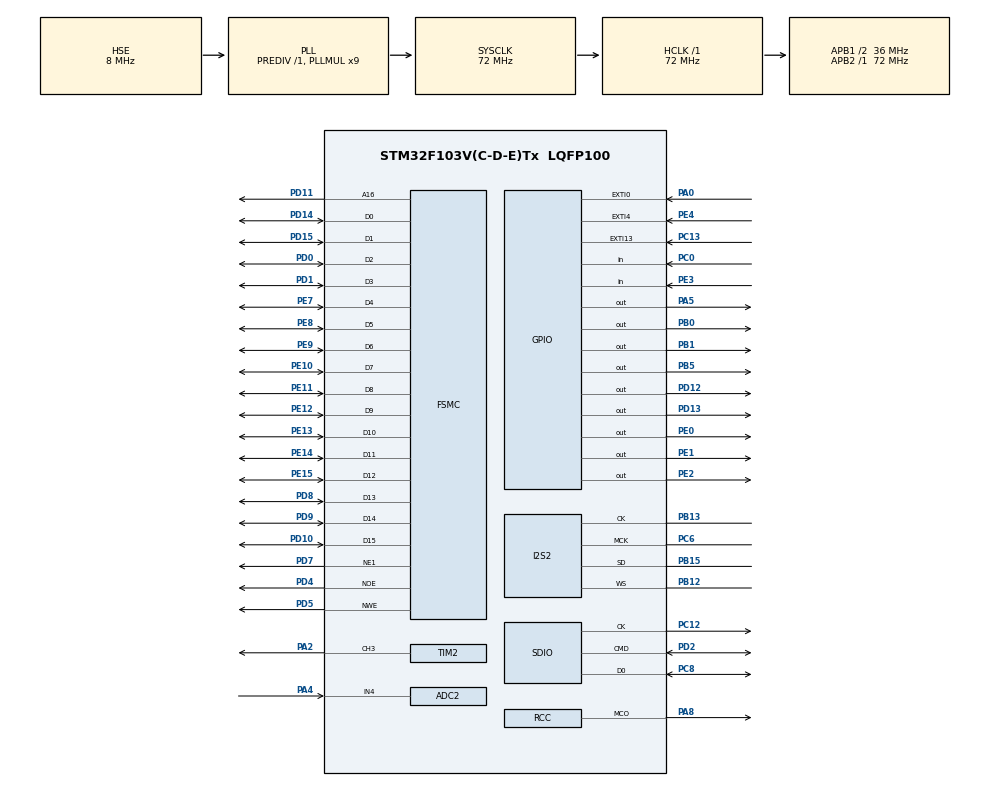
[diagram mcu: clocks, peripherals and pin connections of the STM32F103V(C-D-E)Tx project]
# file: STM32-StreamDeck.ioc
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ADC2.Channel-0\#ChannelRegularConversion=ADC_CHANNEL_4
ADC2.NbrOfConversionFlag=1
ADC2.Rank-0\#ChannelRegularConversion=1
ADC2.SamplingTime-0\#ChannelRegularConversion=ADC_SAMPLETIME_55CYCLES_5
Dma.Request0=SPI2_TX
Dma.SPI2_TX.0.Direction=DMA_MEMORY_TO_PERIPH
Dma.SPI2_TX.0.Instance=DMA1_Channel5
Dma.SPI2_TX.0.MemDataAlignment=DMA_MDATAALIGN_HALFWORD
Dma.SPI2_TX.0.MemInc=DMA_MINC_ENABLE
Dma.SPI2_TX.0.Mode=DMA_CIRCULAR
Dma.SPI2_TX.0.PeriphDataAlignment=DMA_PDATAALIGN_HALFWORD
Dma.SPI2_TX.0.PeriphInc=DMA_PINC_DISABLE
Dma.SPI2_TX.0.Priority=DMA_PRIORITY_LOW
I2S2.AudioFreq=I2S_AUDIOFREQ_16K
I2S2.CPOL=I2S_CPOL_LOW
I2S2.DataFormat=I2S_DATAFORMAT_16B_EXTENDED
I2S2.ErrorAudioFreq=-2.34 %
I2S2.Instance=SPI$Index
I2S2.MCLKOutput=I2S_MCLKOUTPUT_ENABLE
I2S2.RealAudioFreq=15.625 KHz
I2S2.VirtualMode=I2S_MODE_MASTER
Mcu.Family=STM32F1
Mcu.Name=STM32F103V(C-D-E)Tx
Mcu.Package=LQFP100
NVIC.DMA1_Channel5_IRQn=true\:0\:0\:false\:false\:true\:false\:true\:true
NVIC.EXTI0_IRQn=true\:0\:0\:false\:false\:true\:true\:true\:true
NVIC.EXTI15_10_IRQn=true\:0\:0\:false\:false\:true\:true\:true\:true
NVIC.EXTI4_IRQn=true\:0\:0\:false\:false\:true\:true\:true\:true
NVIC.PriorityGroup=NVIC_PRIORITYGROUP_4
NVIC.TIM1_UP_IRQn=true\:0\:0\:false\:false\:true\:true\:true\:true
OSC_IN.Mode=HSE-External-Oscillator
OSC_IN.Signal=RCC_OSC_IN
OSC_OUT.Mode=HSE-External-Oscillator
OSC_OUT.Signal=RCC_OSC_OUT
PA0-WKUP.GPIO_PuPd=GPIO_PULLDOWN
PA0-WKUP.Signal=GPXTI0
PA13.Mode=Serial_Wire
PA13.Signal=SYS_JTMS-SWDIO
PA14.Mode=Serial_Wire
PA14.Signal=SYS_JTCK-SWCLK
PA2.Signal=S_TIM2_CH3
PA4.Signal=ADCx_IN4
PA5.GPIO_Speed=GPIO_SPEED_FREQ_HIGH
PA5.PinState=GPIO_PIN_RESET
PA5.Signal=GPIO_Output
PA8.Mode=Clock-out
PA8.Signal=RCC_MCO
PB0.GPIO_Speed=GPIO_SPEED_FREQ_HIGH
PB0.PinState=GPIO_PIN_SET
PB0.Signal=GPIO_Output
PB1.GPIO_Speed=GPIO_SPEED_FREQ_HIGH
PB1.PinState=GPIO_PIN_SET
PB1.Signal=GPIO_Output
PB12.GPIO_Mode=GPIO_MODE_AF_PP
PB12.GPIO_Speed=GPIO_SPEED_FREQ_HIGH
PB12.Mode=Half_Duplex_Master_TX
PB12.Signal=I2S2_WS
PB13.GPIO_Mode=GPIO_MODE_AF_PP
PB13.GPIO_Speed=GPIO_SPEED_FREQ_HIGH
PB13.Mode=Half_Duplex_Master_TX
PB13.Signal=I2S2_CK
PB15.GPIO_Mode=GPIO_MODE_AF_PP
PB15.GPIO_Speed=GPIO_SPEED_FREQ_HIGH
PB15.Mode=Half_Duplex_Master_TX
PB15.Signal=I2S2_SD
PB5.GPIO_Speed=GPIO_SPEED_FREQ_HIGH
PB5.PinState=GPIO_PIN_SET
PB5.Signal=GPIO_Output
PC0.GPIO_PuPd=GPIO_PULLDOWN
PC0.Signal=GPIO_Input
PC12.Mode=SD_1_bit
PC12.Signal=SDIO_CK
PC13-TAMPER-RTC.GPIO_PuPd=GPIO_PULLDOWN
PC13-TAMPER-RTC.Signal=GPXTI13
PC14-OSC32_IN.Mode=LSE-External-Oscillator
PC14-OSC32_IN.Signal=RCC_OSC32_IN
PC15-OSC32_OUT.Mode=LSE-External-Oscillator
PC15-OSC32_OUT.Signal=RCC_OSC32_OUT
PC6.GPIO_Mode=GPIO_MODE_AF_PP
PC6.GPIO_Speed=GPIO_SPEED_FREQ_HIGH
PC6.Mode=Master_Clock_Activated
PC6.Signal=I2S2_MCK
PC8.Mode=SD_1_bit
PC8.Signal=SDIO_D0
PD0.Mode=16b-d1
PD0.Signal=FSMC_D2
PD1.Mode=16b-d1
PD1.Signal=FSMC_D3
PD10.Mode=16b-d1
PD10.Signal=FSMC_D15
PD11.Mode=A16_1
PD11.Signal=FSMC_A16
PD12.GPIO_Speed=GPIO_SPEED_FREQ_HIGH
PD12.PinState=GPIO_PIN_RESET
PD12.Signal=GPIO_Output
PD13.GPIO_Speed=GPIO_SPEED_FREQ_HIGH
PD13.Signal=GPIO_Output
PD14.Mode=16b-d1
PD14.Signal=FSMC_D0
PD15.Mode=16b-d1
PD15.Signal=FSMC_D1
PD2.Mode=SD_1_bit
PD2.Signal=SDIO_CMD
PD4.Mode=Lcd1
PD4.Signal=FSMC_NOE
PD5.Mode=Lcd1
PD5.Signal=FSMC_NWE
PD7.Mode=NorPsramChipSelect1_1
PD7.Signal=FSMC_NE1
PD8.Mode=16b-d1
PD8.Signal=FSMC_D13
PD9.Mode=16b-d1
PD9.Signal=FSMC_D14
PE0.GPIO_Speed=GPIO_SPEED_FREQ_HIGH
PE0.Signal=GPIO_Output
PE1.GPIO_Speed=GPIO_SPEED_FREQ_HIGH
PE1.Signal=GPIO_Output
PE10.Mode=16b-d1
PE10.Signal=FSMC_D7
PE11.Mode=16b-d1
PE11.Signal=FSMC_D8
PE12.Mode=16b-d1
PE12.Signal=FSMC_D9
PE13.Mode=16b-d1
PE13.Signal=FSMC_D10
PE14.Mode=16b-d1
PE14.Signal=FSMC_D11
PE15.Mode=16b-d1
PE15.Signal=FSMC_D12
PE2.GPIO_Speed=GPIO_SPEED_FREQ_HIGH
PE2.Signal=GPIO_Output
PE3.GPIO_PuPd=GPIO_PULLUP
PE3.Signal=GPIO_Input
PE4.GPIO_ModeDefaultEXTI=GPIO_MODE_IT_FALLING
PE4.GPIO_PuPd=GPIO_PULLUP
PE4.Signal=GPXTI4
PE7.Mode=16b-d1
PE7.Signal=FSMC_D4
PE8.Mode=16b-d1
PE8.Signal=FSMC_D5
PE9.Mode=16b-d1
PE9.Signal=FSMC_D6
ProjectManager.HeapSize=0x200
ProjectManager.StackSize=0x400
ProjectManager.TargetToolchain=STM32CubeIDE
RCC.ADCPresc=RCC_ADCPCLK2_DIV6
RCC.AHBFreq_Value=72000000
RCC.APB1CLKDivider=RCC_HCLK_DIV2
RCC.APB1Freq_Value=36000000
RCC.APB1TimFreq_Value=72000000
RCC.APB2Freq_Value=72000000
RCC.APB2TimFreq_Value=72000000
RCC.HCLKFreq_Value=72000000
RCC.PLLMUL=RCC_PLL_MUL9
RCC.PLLSourceVirtual=RCC_PLLSOURCE_HSE
RCC.RCC_MCOSource=RCC_MCO1SOURCE_PLLCLK
RCC.SYSCLKFreq_VALUE=72000000
RCC.SYSCLKSource=RCC_SYSCLKSOURCE_PLLCLK
RCC.USBFreq_Value=72000000
SDIO.ClockDiv=4
SH.ADCx_IN4.0=ADC2_IN4,IN4
SH.S_TIM2_CH3.0=TIM2_CH3,PWM Generation3 CH3
TIM1.Period=100-1
TIM1.Prescaler=72-1
TIM1.TIM_MasterOutputTrigger=TIM_TRGO_UPDATE
TIM2.Channel-PWM\ Generation3\ CH3=TIM_CHANNEL_3
TIM2.Period=1000-1
TIM2.Prescaler=72-1
TIM2.Pulse-PWM\ Generation3\ CH3=500
TIM2.TIM_MasterOutputTrigger=TIM_TRGO_UPDATE
VP_FATFS_VS_SDIO.Mode=SDIO
VP_TIM1_VS_ClockSourceINT.Mode=Internal
VP_TIM2_VS_ClockSourceINT.Mode=Internal
board=custom

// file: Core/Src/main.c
/* USER CODE BEGIN Header */
/**
  ******************************************************************************
  * @file           : main.c
  * @brief          : Main program body
  ******************************************************************************
  * @attention
  *
  * Copyright (c) 2023 STMicroelectronics.
  * All rights reserved.
  *
  * This software is licensed under terms that can be found in the LICENSE file
  * in the root directory of this software component.
  * If no LICENSE file comes with this software, it is provided AS-IS.
  *
  ******************************************************************************
  */
/* USER CODE END Header */
#include "main.h"
#include "fatfs.h"

/* USER CODE BEGIN Includes */
#include "files.h"
#include "math.h"
#include "pcm.h"
#include <stdio.h>
#include <string.h>
#include "lcdtp.h"
#include "xpt2046.h"
#include "pcm.h"
/* USER CODE END Includes */

/* USER CODE BEGIN PD */
#define usScreenWidth 240
#define usScreenHeight 320
/* USER CODE END PD */

 ADC_HandleTypeDef hadc2;

I2S_HandleTypeDef hi2s2;
DMA_HandleTypeDef hdma_spi2_tx;

SD_HandleTypeDef hsd;

TIM_HandleTypeDef htim1;
TIM_HandleTypeDef htim2;

SRAM_HandleTypeDef hsram1;

/* USER CODE BEGIN PV */

/* Flags */
uint16_t actionFlag = 0, drawGUIFlag = 1, drawButtonsFlag = 1;
uint8_t SDCardStatus = 0;

typedef enum {
  mainMenuTask,
  configMenuTask,
  audiofxConfigTask,
  displayConfigTask,
  dvConfigTask,
  hiddenConfigTask,
  threeFPSRGBTask,
} GUITask;

GUITask curGUITask = mainMenuTask;

 float value = 0.2;
 uint32_t var;
 uint32_t sine_val[100];

 #define PI 3.1415926

 void getSineVal() {
 	for (int i = 0; i < 100; i++) {
 		sine_val[i] = (((sin(i*2*PI/100)+1)*(255/2))*0.5);

 	}
 }
 uint8_t updateLCDStartPlay = 1;
 uint8_t playPCMFlag = 0;
 void HAL_GPIO_EXTI_Callback(uint16_t GPIO_Pin) {
  if (GPIO_Pin == GPIO_PIN_0) {
    if (curGUITask != threeFPSRGBTask) {
      nextSongFlag = 1;
    }
    kay = 1;
  }
	if (GPIO_Pin == GPIO_PIN_13) {
		playPCMFlag = playPCMFlag == 0 ? 1 : 0;
		if (!playPCMFlag) {
			drawGUIFlag = 1;
      drawButtonsFlag = 1;
		}
		updateLCDStartPlay = 1;
 	}
}

// void HAL_TIM_PeriodElapsedCallback(TIM_HandleTypeDef *htim) {
//     if (htim->Instance == TIM1) {
//         if (pcmDataToRead > 0) {
//             HAL_DAC_SetValue(&hdac, DAC_CHANNEL_1, DAC_ALIGN_8B_R, pcmBuffer[pcmBufferIndex]);
//             HAL_DAC_SetValue(&hdac, DAC_CHANNEL_2, DAC_ALIGN_8B_R, pcmBuffer[pcmBufferIndex+1]);
//             pcmBufferIndex += 2;
//             pcmDataToRead--;
//         }
//     }
// }

const uint16_t triangle_wave[]  = {
0x400,0x800,0xc00,0x1000,0x1400,0x1800,0x1c00,0x2000,
0x2400,0x2800,0x2c00,0x3000,0x3400,0x3800,0x3c00,0x4000,
0x4400,0x4800,0x4c00,0x5000,0x5400,0x5800,0x5c00,0x6000,
0x6400,0x6800,0x6c00,0x7000,0x7400,0x7800,0x7c00,0x8000,
0x83ff,0x87ff,0x8bff,0x8fff,0x93ff,0x97ff,0x9bff,0x9fff,
0xa3ff,0xa7ff,0xabff,0xafff,0xb3ff,0xb7ff,0xbbff,0xbfff,
0xc3ff,0xc7ff,0xcbff,0xcfff,0xd3ff,0xd7ff,0xdbff,0xdfff,
0xe3ff,0xe7ff,0xebff,0xefff,0xf3ff,0xf7ff,0xfbff,0xffff,
0xfbff,0xf7ff,0xf3ff,0xefff,0xebff,0xe7ff,0xe3ff,0xdfff,
0xdbff,0xd7ff,0xd3ff,0xcfff,0xcbff,0xc7ff,0xc3ff,0xbfff,
0xbbff,0xb7ff,0xb3ff,0xafff,0xabff,0xa7ff,0xa3ff,0x9fff,
0x9bff,0x97ff,0x93ff,0x8fff,0x8bff,0x87ff,0x83ff,0x8000,
0x7c00,0x7800,0x7400,0x7000,0x6c00,0x6800,0x6400,0x6000,
0x5c00,0x5800,0x5400,0x5000,0x4c00,0x4800,0x4400,0x4000,
0x3c00,0x3800,0x3400,0x3000,0x2c00,0x2800,0x2400,0x2000,
0x1c00,0x1800,0x1400,0x1000,0xc00,0x800,0x400,0x0,
};
const uint16_t sin_tbl_int[91] = {	    0,   572,  1144,  1715,  2286,  2856,  3425,  3993,  4560,  5126,
									 5690,  6252,  6813,  7371,  7927,  8481,  9032,  9580, 10126, 10668,
									11207, 11743, 12275, 12803, 13328, 13848, 14365, 14876, 15384, 15886,
									16384, 16877, 17364, 17847, 18324, 18795, 19261, 19720, 20174, 20622,
									21063, 21498, 21926, 22348, 22763, 23170, 23571, 23965, 24351, 24730,
									25102, 25466, 25822, 26170, 26510, 26842, 27166, 27482, 27789, 28088,
									28378, 28660, 28932, 29197, 29452, 29698, 29935, 30163, 30382, 30592,
									30792, 30983, 31164, 31336, 31499, 31651, 31795, 31928, 32052, 32166,
									32270, 32365, 32449, 32524, 32588, 32643, 32688, 32723, 32748, 32763,
									32768 };
/* Strings */
char * pStr = 0, cStr [10];

uint16_t inputSrc = 0 /* 0 = SD | 1 = 3.5mm */;		// See xpt2046.c \ audiofxConfig()
int kay = 0 /* K1 flag */, kerry = 0 /* K2 flag */;
uint16_t trueTone = 0 /* LDR trigger */, colourP = 0;	// Display colour preset
uint16_t shock = 0 /* Dynamic vibration trigger */, buzz = 1;	// 1 = Mildest | 3 = Strongest
uint16_t ruler;		// ADC2
uint16_t chovy[3];	// ADC2 Read buffer
/* USER CODE END PV */

void SystemClock_Config(void);
static void MX_GPIO_Init(void);
static void MX_FSMC_Init(void);
static void MX_SDIO_SD_Init(void);
static void MX_TIM1_Init(void);
static void MX_TIM2_Init(void);
static void MX_DMA_Init(void);
static void MX_I2S2_Init(void);
static void MX_ADC2_Init(void);
/* USER CODE BEGIN PFP */
uint8_t virtualAudioPlayerTask() {
	if (playPCMFlag) {
		// LCD_Clear (0, 0, 240, 320, BACKGROUND);
		scanFiles("0:/");
		return 1;
	} else {
		return 0;
	}
}
/* USER CODE END PFP */

/* USER CODE BEGIN 0 */
uint16_t testingIntensity = 0;
void dvModule (void) {
	// intensity = getAudioIntensity();
//  testingIntensity++;
//  if (testingIntensity > 100) {
//    testingIntensity = 0;
//  }
//	currentAudioIntensity = testingIntensity;			// For testing purposes

	/**
	 * I originally planned to change the voltage
	 * After testing I found out adjusting the vibration time achieves the same effect,
	 * and is way more doable than the above operation,
	 * so here we are ;)
	 */
	if (shock == 1) {
		// switch (buzz) {
		// 	case 1:
		// 		HAL_GPIO_WritePin(GPIOA, GPIO_PIN_5, GPIO_PIN_RESET);
		// 		HAL_Delay(100 - (currentAudioIntensity / 3));
		// 		HAL_GPIO_WritePin(GPIOA, GPIO_PIN_5,   GPIO_PIN_SET);
		// 		break;
		// 	case 2:
		// 		HAL_GPIO_WritePin(GPIOA, GPIO_PIN_5,   GPIO_PIN_RESET);
		// 		HAL_Delay(100 - (currentAudioIntensity * 2 / 3));
		// 		HAL_GPIO_WritePin(GPIOA, GPIO_PIN_5, GPIO_PIN_SET);
		// 		break;
		// 	case 3:
		// 		HAL_GPIO_WritePin(GPIOA, GPIO_PIN_5,   GPIO_PIN_RESET);
		// 		HAL_Delay(100 - currentAudioIntensity);
		// 		HAL_GPIO_WritePin(GPIOA, GPIO_PIN_5, GPIO_PIN_SET);
		// 		break;
		// }
    currentAudioIntensity = currentAudioIntensity / 6 * (buzz+3);
    if (buzz == 3 ) {
      currentAudioIntensity = currentAudioIntensity * 1.5;
      currentAudioIntensity > 1000 ? currentAudioIntensity = 1000 : currentAudioIntensity;

    }
    __HAL_TIM_SET_COMPARE(&htim2, TIM_CHANNEL_3, currentAudioIntensity);
	}
	return;
}

/* USER CODE END 0 */

int main(void)
{

  /* MCU Configuration--------------------------------------------------------*/

  /* Reset of all peripherals, Initializes the Flash interface and the Systick. */
  HAL_Init();

  /* Configure the system clock */
  SystemClock_Config();

  /* Initialize all configured peripherals */
  MX_GPIO_Init();
  MX_FSMC_Init();
  MX_SDIO_SD_Init();
  MX_FATFS_Init();
  MX_TIM1_Init();
  MX_TIM2_Init();
  MX_DMA_Init();
  MX_I2S2_Init();
  MX_ADC2_Init();
  /* USER CODE BEGIN 2 */

	FATFS myFATFS;
	FIL myFILE;
	UINT numberofbytes;
	char myPath[] = "TEST.TXT\0";
	char myData[] = "Hello World\0";
	FRESULT res;

	res = f_mount(&myFATFS,SDPath,1);
	if (res == FR_OK)
	{
    SDCardStatus = 1;
		HAL_GPIO_WritePin(GPIOB, GPIO_PIN_0,GPIO_PIN_RESET);
		f_open(&myFILE, myPath, FA_WRITE |FA_CREATE_ALWAYS);
		f_write(&myFILE, myData, sizeof(myData), &numberofbytes);
		f_close(&myFILE);
		HAL_Delay(1000);
		HAL_GPIO_WritePin(GPIOB, GPIO_PIN_1,GPIO_PIN_RESET);
	}
	else
	{
    SDCardStatus = 0;
		HAL_GPIO_WritePin(GPIOB, GPIO_PIN_5,GPIO_PIN_RESET);
	}

  macXPT2046_CS_DISABLE();
  LCD_INIT();
  /* Boot splash */
  pStr = "Welcome to Stream Deck!";
  LCD_DrawString_Color ( ( usScreenWidth - ( strlen ( pStr ) - 7 ) * WIDTH_EN_CHAR ) >> 2, usScreenHeight >> 1, pStr, BACKGROUND, BLACK );
  HAL_Delay(1000);
  LCD_Clear(0, 0, 240, 320, BACKGROUND);
//  HAL_GPIO_WritePin(GPIOA, GPIO_PIN_5,   GPIO_PIN_RESET);		// Debugging
  HAL_ADCEx_Calibration_Start(&hadc2);
  HAL_ADC_Start(&hadc2);
  HAL_ADC_PollForConversion(&hadc2, 100);
  while( ! XPT2046_Touch_Calibrate () );
  LCD_Clear(0, 0, 240, 320, BACKGROUND);

  /* USER CODE END 2 */

  /* Infinite loop */
  while (1)
    {

    /* USER CODE BEGIN 3 */
		// goto mainMenu;

	if (!virtualAudioPlayerTask()) { // this is a virtual task for the MP3 player with its own loop

      ruler = HAL_ADC_GetValue(&hadc2);
      adaptiveBrightness(trueTone, ruler);
	switch(curGUITask) { // the GUI task
      case audiofxConfigTask:
      if (drawGUIFlag) {
        drawGUIFlag = 0;
			LCD_Clear (0, 0, 240, 320, BACKGROUND);

			/* Button rendering */
			LCD_DrawBox(8, 8, 48, 48, BLACK);
			pStr = "BACK";
			LCD_DrawString_Color (16, 24, pStr, BACKGROUND, BLACK);

			/* Input source selection */
			LCD_DrawBox(184, 64, 48, 48, GREEN);
			pStr = "Input source";
			LCD_DrawString_Color (16, 80, pStr, BACKGROUND, BLACK);

			if (inputSrc == 0) {
				LCD_DrawBox(184, 64, 48, 48, GREEN);
				pStr = "SD";
				LCD_DrawString_Color (200, 80, pStr, BACKGROUND, GREEN);
			} else {
				LCD_DrawBox(184, 64, 48, 48, ORANGE);
				pStr = "3.5mm";
				LCD_DrawString_Color (192, 80, pStr, BACKGROUND, ORANGE);
			}

			pStr = "Voice effect";
			LCD_DrawString_Color (16, 120, pStr, BACKGROUND, BLACK);

			pStr = "Selected";
			LCD_DrawString_Color (120, 120, pStr, BACKGROUND, GREEN);

			/* Title */
			pStr = "Audio FX";
			LCD_DrawString_Color (64, 24, pStr, BACKGROUND, BLACK );
      }
      if (drawButtonsFlag) {
        drawButtonsFlag = 0;
				/* Voice effect selection */
					if (fxMode == 11) {
						LCD_DrawBox(32, 142, 48, 48, GREEN);
						pStr = "No";
						LCD_DrawString_Color (34, 150, pStr, BACKGROUND, GREEN);
						pStr = "effect";
						LCD_DrawString_Color (34, 166, pStr, BACKGROUND, GREEN);
					}
					else {
						LCD_DrawBox(32, 142, 48, 48, BLACK);
						pStr = "No";
						LCD_DrawString_Color (34, 150, pStr, BACKGROUND, BLACK);
						pStr = "effect";
						LCD_DrawString_Color (34, 166, pStr, BACKGROUND, BLACK);
					}

					if (fxMode == 12) {
						LCD_DrawBox(92, 142, 48, 48, GREEN);
						pStr = "Deep";
						LCD_DrawString_Color (94, 150, pStr, BACKGROUND, GREEN);
						pStr = "pitch";
						LCD_DrawString_Color (94, 166, pStr, BACKGROUND, GREEN);
					}
					else {
						LCD_DrawBox(92, 142, 48, 48, BLACK);
						pStr = "Deep";
						LCD_DrawString_Color (94, 150, pStr, BACKGROUND, BLACK);
						pStr = "pitch";
						LCD_DrawString_Color (94, 166, pStr, BACKGROUND, BLACK);
					}

					if (fxMode == 13) {
						LCD_DrawBox(152, 142, 48, 48, GREEN);
						pStr = "High";
						LCD_DrawString_Color (154, 150, pStr, BACKGROUND, GREEN);
						pStr = "pitch";
						LCD_DrawString_Color (154, 166, pStr, BACKGROUND, GREEN);
					}
					else {
						LCD_DrawBox(152, 142, 48, 48, BLACK);
						pStr = "High";
						LCD_DrawString_Color (154, 150, pStr, BACKGROUND, BLACK);
						pStr = "pitch";
						LCD_DrawString_Color (154, 166, pStr, BACKGROUND, BLACK);
					}

					if (fxMode == 21) {
						LCD_DrawBox(32, 198, 48, 48, GREEN);
						pStr = "Robot";
						LCD_DrawString_Color (34, 214, pStr, BACKGROUND, GREEN);
					}
					else {
						LCD_DrawBox(32, 198, 48, 48, BLACK);
						pStr = "Robot";
						LCD_DrawString_Color (34, 214, pStr, BACKGROUND, BLACK);
					}

					if (fxMode == 22) {
						LCD_DrawBox(92, 198, 48, 48, GREEN);
						pStr = "Grand";
						LCD_DrawString_Color (94, 214, pStr, BACKGROUND, GREEN);
					}
					else {
						LCD_DrawBox(92, 198, 48, 48, BLACK);
						pStr = "Grand";
						LCD_DrawString_Color (94, 214, pStr, BACKGROUND, BLACK);
					}

					if (fxMode == 23) {
						LCD_DrawBox(152, 198, 48, 48, GREEN);
						pStr = "Ghost";
						LCD_DrawString_Color (154, 214, pStr, BACKGROUND, GREEN);
					}
					else {
						LCD_DrawBox(152, 198, 48, 48, BLACK);
						pStr = "Ghost";
						LCD_DrawString_Color (154, 214, pStr, BACKGROUND, BLACK);
					}
				}
				if ( ucXPT2046_TouchFlag == 1 ) {
					actionFlag = audiofxConfig();
					ucXPT2046_TouchFlag = 0;
					switch (actionFlag) {
						case 0:
						  curGUITask = configMenuTask;
						  drawGUIFlag = 1;
						  break;
						case 1:
							if (inputSrc == 0) {
								LCD_Clear (184, 64, 48, 48, BACKGROUND);
								LCD_DrawBox(184, 64, 48, 48, ORANGE);
								pStr = "3.5mm";
								LCD_DrawString_Color (192, 80, pStr, BACKGROUND, ORANGE);
								inputSrc++;
							} else {
								LCD_Clear (184, 64, 48, 48, BACKGROUND);
								LCD_DrawBox(184, 64, 48, 48, GREEN);
								pStr = "SD";
								LCD_DrawString_Color (200, 80, pStr, BACKGROUND, GREEN );
								inputSrc--;
							}
							break;
						// Toggle FX
						case 11: drawButtonsFlag = 1; fxMode = 11; break;
						case 12: drawButtonsFlag = 1; fxMode = 12; break;
						case 13: drawButtonsFlag = 1; fxMode = 13; break;
						case 21: drawButtonsFlag = 1; fxMode = 21; break;
						case 22: drawButtonsFlag = 1; fxMode = 22; break;
						case 23: drawButtonsFlag = 1; fxMode = 23; break;
					}
				}
        break;
      case displayConfigTask:
      if (drawGUIFlag) {
      drawGUIFlag = 0;

			LCD_Clear (0, 0, 240, 320, BACKGROUND);

			/* Button rendering */
			LCD_DrawBox(8, 8, 48, 48, BLACK);
			pStr = "BACK";
			LCD_DrawString_Color (16, 24, pStr, BACKGROUND, BLACK );

			/* LDR brightness control */
			pStr = "Auto";
			LCD_DrawString_Color (16, 72, pStr, BACKGROUND, BLACK );

			pStr = "Brightness";
			LCD_DrawString_Color (16, 88, pStr, BACKGROUND, BLACK );

			if (trueTone == 1) {
				LCD_DrawBox(184, 64, 48, 48, GREEN);
				pStr = "ON";
				LCD_DrawString_Color (200, 80, pStr, BACKGROUND, GREEN);
			} else {
				LCD_DrawBox(184, 64, 48, 48, ORANGE);
				pStr = "OFF";
				LCD_DrawString_Color (200, 80, pStr, BACKGROUND, ORANGE);
			}

			/* Breathing light */
			LCD_DrawBox(184, 120, 48, 48, BLACK);
			pStr = "Colour";
			LCD_DrawString_Color (16, 128, pStr, BACKGROUND, BLACK);

			pStr = "preset";
			LCD_DrawString_Color (16, 144, pStr, BACKGROUND, BLACK);

			sprintf(cStr, "%d", colourP);
			switch (colourP) {
				case 0:
					LCD_DrawBox(184, 120, 48, 48, RED);
					LCD_DrawString_Color ( 204, 136, cStr, BACKGROUND, RED);
					break;
				case 1:
					LCD_DrawBox(184, 120, 48, 48, ORANGE);
					LCD_DrawString_Color ( 204, 136, cStr, BACKGROUND, ORANGE);
					break;
				case 2:
					LCD_DrawBox(184, 120, 48, 48, YELLOW);
					LCD_DrawString_Color ( 204, 136, cStr, BACKGROUND, YELLOW);
					break;
				case 3:
					LCD_DrawBox(184, 120, 48, 48, GREEN);
					LCD_DrawString_Color ( 204, 136, cStr, BACKGROUND, GREEN);
					break;
				case 4:
					LCD_DrawBox(184, 120, 48, 48, CYAN);
					LCD_DrawString_Color ( 204, 136, cStr, BACKGROUND, CYAN);
					break;
				case 5:
					LCD_DrawBox(184, 120, 48, 48, BLUE);
					LCD_DrawString_Color ( 204, 136, cStr, BACKGROUND, BLUE);
					break;
				case 6:
					LCD_DrawBox(184, 120, 48, 48, MAGENTA);
					LCD_DrawString_Color ( 204, 136, cStr, BACKGROUND, MAGENTA);
					break;
			}
			LCD_DrawBox(184, 176, 48, 48, BLACK);
			pStr = "Start";
			LCD_DrawString_Color (16, 184, pStr, BACKGROUND, BLACK);

			pStr = "RGB";
			LCD_DrawString_Color (16, 200, pStr, BACKGROUND, BLACK);

			/* Title */
			pStr = "Display options";
			LCD_DrawString_Color ( 64, 24, pStr, BACKGROUND, BLACK);
      }
				// Showing LDR value on screen
				// sprintf(chovy, "%x",  ruler);
				// LCD_Clear(128, 88, 48, 16, BACKGROUND);
				// LCD_DrawString(128, 88, chovy);

				// drawButtonsFlag isn't needed as these buttons are only rendered once the touchscreen senses input
				if ( ucXPT2046_TouchFlag == 1 ) {
					actionFlag = backButton();
					ucXPT2046_TouchFlag = 0;
					switch (actionFlag) {
						case 0:
              drawGUIFlag = 1;
              curGUITask = configMenuTask;
						case 1:
							if (trueTone == 0) {
								LCD_Clear (184, 64, 48, 48, BACKGROUND);
								LCD_DrawBox(184, 64, 48, 48, GREEN);
								pStr = "ON";
								LCD_DrawString_Color (200, 80, pStr, BACKGROUND, GREEN);
								trueTone++;
							} else {
								LCD_Clear (184, 64, 48, 48, BACKGROUND);
								LCD_DrawBox(184, 64, 48, 48, ORANGE);
								pStr = "OFF";
								LCD_DrawString_Color (200, 80, pStr, BACKGROUND, ORANGE);
								trueTone--;
							}
							break;
						case 2:
							colourP = (colourP == 6) ? 0 : colourP + 1;
							sprintf(cStr, "%d", colourP);
							switch (colourP) {
								case 0:
									LCD_DrawBox(184, 120, 48, 48, RED);
									LCD_DrawString_Color ( 204, 136, cStr, BACKGROUND, RED);
									break;
								case 1:
									LCD_DrawBox(184, 120, 48, 48, ORANGE);
									LCD_DrawString_Color ( 204, 136, cStr, BACKGROUND, ORANGE);
									break;
								case 2:
									LCD_DrawBox(184, 120, 48, 48, YELLOW);
									LCD_DrawString_Color ( 204, 136, cStr, BACKGROUND, YELLOW);
									break;
								case 3:
									LCD_DrawBox(184, 120, 48, 48, GREEN);
									LCD_DrawString_Color ( 204, 136, cStr, BACKGROUND, GREEN);
									break;
								case 4:
									LCD_DrawBox(184, 120, 48, 48, CYAN);
									LCD_DrawString_Color ( 204, 136, cStr, BACKGROUND, CYAN);
									break;
								case 5:
									LCD_DrawBox(184, 120, 48, 48, BLUE);
									LCD_DrawString_Color ( 204, 136, cStr, BACKGROUND, BLUE);
									break;
								case 6:
									LCD_DrawBox(184, 120, 48, 48, MAGENTA);
									LCD_DrawString_Color ( 204, 136, cStr, BACKGROUND, MAGENTA);
									break;
							}
							break;
						case 3: drawGUIFlag = 1; curGUITask = threeFPSRGBTask; break;
					}
				}
        break;
      case dvConfigTask:
      if (drawGUIFlag) {
			LCD_Clear (0, 0, 240, 320, BACKGROUND);

			/* Button rendering */
			LCD_DrawBox(8, 8, 48, 48, BLACK);
			pStr = "BACK";
			LCD_DrawString_Color (16, 24, pStr, BACKGROUND, BLACK );

			/* Toggle */
			pStr = "Enable";
			LCD_DrawString_Color (16, 72, pStr, BACKGROUND, BLACK );

			pStr = "effect";
			LCD_DrawString_Color (16, 88, pStr, BACKGROUND, BLACK );

			if (shock == 1) {
				LCD_DrawBox(184, 64, 48, 48, GREEN);
				pStr = "ON";
				LCD_DrawString_Color (200, 80, pStr, BACKGROUND, GREEN);
			} else {
				LCD_DrawBox(184, 64, 48, 48, ORANGE);
				pStr = "OFF";
				LCD_DrawString_Color (200, 80, pStr, BACKGROUND, ORANGE);
			}

			/* Peak strength */
			pStr = "Max vibration";
			LCD_DrawString_Color (16, 120, pStr, BACKGROUND, BLACK );

			pStr = "strength";
			LCD_DrawString_Color (16, 136, pStr, BACKGROUND, BLACK );

			pStr = "1=Mild | 3=Strong";
			LCD_DrawString_Color (16, 136, pStr, BACKGROUND, BLACK );

			/* Title */
			pStr = "Dynamic Vibration";
			LCD_DrawString_Color (64, 24, pStr, BACKGROUND, BLACK );

			sprintf(cStr, "%d", buzz);
			switch (buzz) {
				case 1:
					LCD_DrawBox(184, 120, 48, 48, CYAN);
					LCD_DrawString_Color (204, 136, cStr, BACKGROUND, CYAN);
					break;
				case 2:
					LCD_DrawBox(184, 120, 48, 48, GREEN);
					LCD_DrawString_Color (204, 136, cStr, BACKGROUND, GREEN);
					break;
				case 3:
					LCD_DrawBox(184, 120, 48, 48, ORANGE);
					LCD_DrawString_Color (204, 136, cStr, BACKGROUND, ORANGE);
					break;
			}
      drawGUIFlag = 0;
      drawButtonsFlag = 0;
      }
				if ( ucXPT2046_TouchFlag == 1 ) {
					actionFlag = backButton();
					ucXPT2046_TouchFlag = 0;
					switch (actionFlag) {
						case 0:
              drawGUIFlag = 1;
              curGUITask = configMenuTask;
              break;
						case 1:		// Toggle
							if (shock == 0) {
								LCD_Clear (184, 64, 48, 48, BACKGROUND);
								LCD_DrawBox(184, 64, 48, 48, GREEN);
								pStr = "ON";
								LCD_DrawString_Color (200, 80, pStr, BACKGROUND, GREEN);
								shock = 1;
							} else {
								LCD_Clear (184, 64, 48, 48, BACKGROUND);
								LCD_DrawBox(184, 64, 48, 48, ORANGE);
								pStr = "OFF";
								LCD_DrawString_Color (200, 80, pStr, BACKGROUND, ORANGE);
								shock = 0;
							}
							break;
						case 2:		// Cascade
							buzz = (buzz == 3) ? 1 : buzz + 1;
							sprintf(cStr, "%d", buzz);
							switch (buzz) {
								case 1:
									LCD_DrawBox(184, 120, 48, 48, CYAN);
									LCD_DrawString_Color ( 204, 136, cStr, BACKGROUND, CYAN);
									break;
								case 2:
									LCD_DrawBox(184, 120, 48, 48, GREEN);
									LCD_DrawString_Color ( 204, 136, cStr, BACKGROUND, GREEN);
									break;
								case 3:
									LCD_DrawBox(184, 120, 48, 48, ORANGE);
									LCD_DrawString_Color ( 204, 136, cStr, BACKGROUND, ORANGE);
									break;
							}
					}
				}
        break;
      case hiddenConfigTask:
      if (drawGUIFlag) {
      drawGUIFlag = 0;
			LCD_Clear (0, 0, 240, 320, BACKGROUND);

			/* Button rendering */
			LCD_DrawBox(8, 8, 48, 48, BLACK);
			pStr = "BACK";
			LCD_DrawString_Color ( 16, 24, pStr, BACKGROUND, BLACK );

			/* Breathing light */
			LCD_DrawBox(184, 64, 48, 48, BLACK);
			pStr = "MLG";
			LCD_DrawString_Color ( 16, 72, pStr, BACKGROUND, BLACK );

			pStr = "RGB";
			LCD_DrawString_Color ( 16, 88, pStr, BACKGROUND, BLACK );

			/* Title */
			pStr = "Advanced options";
			LCD_DrawString_Color ( 64, 24, pStr, BACKGROUND, BLACK );
      }

				if ( ucXPT2046_TouchFlag == 1 ) {
					actionFlag = backButton();
					ucXPT2046_TouchFlag = 0;
					switch (actionFlag) {
						case 0:
              drawGUIFlag = 1;
              curGUITask = configMenuTask;
						case 1:
							colourP = 7;
              curGUITask = threeFPSRGBTask;
					}
				}
        break;
      case threeFPSRGBTask:
			ruler = HAL_ADC_GetValue(&hadc2);
			adaptiveBrightness(trueTone, ruler);

			switch (colourP) {
				case 0:
					LCD_Clear (0, 0, 240, 320, RED_C);
					pStr = "Press K1 to exit";
					LCD_DrawString_Color ( ( usScreenWidth - ( strlen ( pStr ) - 7 ) * WIDTH_EN_CHAR ) >> 2, usScreenHeight >> 1, pStr, BACKGROUND, RED_C);

					LCD_Clear (0, 0, 240, 320, RED_B);
					pStr = "Press K1 to exit";
					LCD_DrawString_Color ( ( usScreenWidth - ( strlen ( pStr ) - 7 ) * WIDTH_EN_CHAR ) >> 2, usScreenHeight >> 1, pStr, BACKGROUND, RED_B);

					LCD_Clear (0, 0, 240, 320, RED_A);
					pStr = "Press K1 to exit";
					LCD_DrawString_Color ( ( usScreenWidth - ( strlen ( pStr ) - 7 ) * WIDTH_EN_CHAR ) >> 2, usScreenHeight >> 1, pStr, BACKGROUND, RED_A);

					LCD_Clear (0, 0, 240, 320, RED);
					pStr = "Press K1 to exit";
					LCD_DrawString_Color ( ( usScreenWidth - ( strlen ( pStr ) - 7 ) * WIDTH_EN_CHAR ) >> 2, usScreenHeight >> 1, pStr, BACKGROUND, RED);

					LCD_Clear (0, 0, 240, 320, RED_A);
					pStr = "Press K1 to exit";
					LCD_DrawString_Color ( ( usScreenWidth - ( strlen ( pStr ) - 7 ) * WIDTH_EN_CHAR ) >> 2, usScreenHeight >> 1, pStr, BACKGROUND, RED_A);

					LCD_Clear (0, 0, 240, 320, RED_B);
					pStr = "Press K1 to exit";
					LCD_DrawString_Color ( ( usScreenWidth - ( strlen ( pStr ) - 7 ) * WIDTH_EN_CHAR ) >> 2, usScreenHeight >> 1, pStr, BACKGROUND, RED_B);

					LCD_Clear (0, 0, 240, 320, RED_C);
					pStr = "Press K1 to exit";
					LCD_DrawString_Color ( ( usScreenWidth - ( strlen ( pStr ) - 7 ) * WIDTH_EN_CHAR ) >> 2, usScreenHeight >> 1, pStr, BACKGROUND, RED_C);

					break;
				case 1:
					LCD_Clear (0, 0, 240, 320, ORANGE_C);
					pStr = "Press K1 to exit";
					LCD_DrawString_Color ( ( usScreenWidth - ( strlen ( pStr ) - 7 ) * WIDTH_EN_CHAR ) >> 2, usScreenHeight >> 1, pStr, BACKGROUND, ORANGE_C);

					LCD_Clear (0, 0, 240, 320, ORANGE_B);
					pStr = "Press K1 to exit";
					LCD_DrawString_Color ( ( usScreenWidth - ( strlen ( pStr ) - 7 ) * WIDTH_EN_CHAR ) >> 2, usScreenHeight >> 1, pStr, BACKGROUND, ORANGE_B);

					LCD_Clear (0, 0, 240, 320, ORANGE_A);
					pStr = "Press K1 to exit";
					LCD_DrawString_Color ( ( usScreenWidth - ( strlen ( pStr ) - 7 ) * WIDTH_EN_CHAR ) >> 2, usScreenHeight >> 1, pStr, BACKGROUND, ORANGE_A);

					LCD_Clear (0, 0, 240, 320, ORANGE);
					pStr = "Press K1 to exit";
					LCD_DrawString_Color ( ( usScreenWidth - ( strlen ( pStr ) - 7 ) * WIDTH_EN_CHAR ) >> 2, usScreenHeight >> 1, pStr, BACKGROUND, ORANGE);

					LCD_Clear (0, 0, 240, 320, ORANGE_A);
					pStr = "Press K1 to exit";
					LCD_DrawString_Color ( ( usScreenWidth - ( strlen ( pStr ) - 7 ) * WIDTH_EN_CHAR ) >> 2, usScreenHeight >> 1, pStr, BACKGROUND, ORANGE_A);

					LCD_Clear (0, 0, 240, 320, ORANGE_B);
					pStr = "Press K1 to exit";
					LCD_DrawString_Color ( ( usScreenWidth - ( strlen ( pStr ) - 7 ) * WIDTH_EN_CHAR ) >> 2, usScreenHeight >> 1, pStr, BACKGROUND, ORANGE_B);

					LCD_Clear (0, 0, 240, 320, ORANGE_C);
					pStr = "Press K1 to exit";
					LCD_DrawString_Color ( ( usScreenWidth - ( strlen ( pStr ) - 7 ) * WIDTH_EN_CHAR ) >> 2, usScreenHeight >> 1, pStr, BACKGROUND, ORANGE_C);

					break;
				case 2:
					LCD_Clear (0, 0, 240, 320, YELLOW_C);
					pStr = "Press K1 to exit";
					LCD_DrawString_Color ( ( usScreenWidth - ( strlen ( pStr ) - 7 ) * WIDTH_EN_CHAR ) >> 2, usScreenHeight >> 1, pStr, BACKGROUND, YELLOW_C);

					LCD_Clear (0, 0, 240, 320, YELLOW_B);
					pStr = "Press K1 to exit";
					LCD_DrawString_Color ( ( usScreenWidth - ( strlen ( pStr ) - 7 ) * WIDTH_EN_CHAR ) >> 2, usScreenHeight >> 1, pStr, BACKGROUND, YELLOW_B);

					LCD_Clear (0, 0, 240, 320, YELLOW_A);
					pStr = "Press K1 to exit";
					LCD_DrawString_Color ( ( usScreenWidth - ( strlen ( pStr ) - 7 ) * WIDTH_EN_CHAR ) >> 2, usScreenHeight >> 1, pStr, BACKGROUND, YELLOW_A);

					LCD_Clear (0, 0, 240, 320, YELLOW);
					pStr = "Press K1 to exit";
					LCD_DrawString_Color ( ( usScreenWidth - ( strlen ( pStr ) - 7 ) * WIDTH_EN_CHAR ) >> 2, usScreenHeight >> 1, pStr, BACKGROUND, YELLOW);

					LCD_Clear (0, 0, 240, 320, YELLOW_A);
					pStr = "Press K1 to exit";
					LCD_DrawString_Color ( ( usScreenWidth - ( strlen ( pStr ) - 7 ) * WIDTH_EN_CHAR ) >> 2, usScreenHeight >> 1, pStr, BACKGROUND, YELLOW_A);

					LCD_Clear (0, 0, 240, 320, YELLOW_B);
					pStr = "Press K1 to exit";
					LCD_DrawString_Color ( ( usScreenWidth - ( strlen ( pStr ) - 7 ) * WIDTH_EN_CHAR ) >> 2, usScreenHeight >> 1, pStr, BACKGROUND, YELLOW_B);

					LCD_Clear (0, 0, 240, 320, YELLOW_C);
					pStr = "Press K1 to exit";
					LCD_DrawString_Color ( ( usScreenWidth - ( strlen ( pStr ) - 7 ) * WIDTH_EN_CHAR ) >> 2, usScreenHeight >> 1, pStr, BACKGROUND, YELLOW_C);

					break;
				case 3:
					LCD_Clear (0, 0, 240, 320, GREEN_C);
					pStr = "Press K1 to exit";
					LCD_DrawString_Color ( ( usScreenWidth - ( strlen ( pStr ) - 7 ) * WIDTH_EN_CHAR ) >> 2, usScreenHeight >> 1, pStr, BACKGROUND, GREEN_C);

					LCD_Clear (0, 0, 240, 320, GREEN_B);
					pStr = "Press K1 to exit";
					LCD_DrawString_Color ( ( usScreenWidth - ( strlen ( pStr ) - 7 ) * WIDTH_EN_CHAR ) >> 2, usScreenHeight >> 1, pStr, BACKGROUND, GREEN_B);

					LCD_Clear (0, 0, 240, 320, GREEN_A);
					pStr = "Press K1 to exit";
					LCD_DrawString_Color ( ( usScreenWidth - ( strlen ( pStr ) - 7 ) * WIDTH_EN_CHAR ) >> 2, usScreenHeight >> 1, pStr, BACKGROUND, GREEN_A);

					LCD_Clear (0, 0, 240, 320, GREEN);
					pStr = "Press K1 to exit";
					LCD_DrawString_Color ( ( usScreenWidth - ( strlen ( pStr ) - 7 ) * WIDTH_EN_CHAR ) >> 2, usScreenHeight >> 1, pStr, BACKGROUND, GREEN);

					LCD_Clear (0, 0, 240, 320, GREEN_A);
					pStr = "Press K1 to exit";
					LCD_DrawString_Color ( ( usScreenWidth - ( strlen ( pStr ) - 7 ) * WIDTH_EN_CHAR ) >> 2, usScreenHeight >> 1, pStr, BACKGROUND, GREEN_A);

					LCD_Clear (0, 0, 240, 320, GREEN_B);
					pStr = "Press K1 to exit";
					LCD_DrawString_Color ( ( usScreenWidth - ( strlen ( pStr ) - 7 ) * WIDTH_EN_CHAR ) >> 2, usScreenHeight >> 1, pStr, BACKGROUND, GREEN_B);

					LCD_Clear (0, 0, 240, 320, GREEN_C);
					pStr = "Press K1 to exit";
					LCD_DrawString_Color ( ( usScreenWidth - ( strlen ( pStr ) - 7 ) * WIDTH_EN_CHAR ) >> 2, usScreenHeight >> 1, pStr, BACKGROUND, GREEN_C);

					break;
				case 4:
					LCD_Clear (0, 0, 240, 320, CYAN_C);
					pStr = "Press K1 to exit";
					LCD_DrawString_Color ( ( usScreenWidth - ( strlen ( pStr ) - 7 ) * WIDTH_EN_CHAR ) >> 2, usScreenHeight >> 1, pStr, BACKGROUND, CYAN_C);

					LCD_Clear (0, 0, 240, 320, CYAN_B);
					pStr = "Press K1 to exit";
					LCD_DrawString_Color ( ( usScreenWidth - ( strlen ( pStr ) - 7 ) * WIDTH_EN_CHAR ) >> 2, usScreenHeight >> 1, pStr, BACKGROUND, CYAN_B);

					LCD_Clear (0, 0, 240, 320, CYAN_A);
					pStr = "Press K1 to exit";
					LCD_DrawString_Color ( ( usScreenWidth - ( strlen ( pStr ) - 7 ) * WIDTH_EN_CHAR ) >> 2, usScreenHeight >> 1, pStr, BACKGROUND, CYAN_A);

					LCD_Clear (0, 0, 240, 320, CYAN);
					pStr = "Press K1 to exit";
					LCD_DrawString_Color ( ( usScreenWidth - ( strlen ( pStr ) - 7 ) * WIDTH_EN_CHAR ) >> 2, usScreenHeight >> 1, pStr, BACKGROUND, CYAN);

					LCD_Clear (0, 0, 240, 320, CYAN_A);
					pStr = "Press K1 to exit";
					LCD_DrawString_Color ( ( usScreenWidth - ( strlen ( pStr ) - 7 ) * WIDTH_EN_CHAR ) >> 2, usScreenHeight >> 1, pStr, BACKGROUND, CYAN_A);

					LCD_Clear (0, 0, 240, 320, CYAN_B);
					pStr = "Press K1 to exit";
					LCD_DrawString_Color ( ( usScreenWidth - ( strlen ( pStr ) - 7 ) * WIDTH_EN_CHAR ) >> 2, usScreenHeight >> 1, pStr, BACKGROUND, CYAN_B);

					LCD_Clear (0, 0, 240, 320, CYAN_C);
					pStr = "Press K1 to exit";
					LCD_DrawString_Color ( ( usScreenWidth - ( strlen ( pStr ) - 7 ) * WIDTH_EN_CHAR ) >> 2, usScreenHeight >> 1, pStr, BACKGROUND, CYAN_C);

					break;
				case 5:
					LCD_Clear (0, 0, 240, 320, BLUE_C);
					pStr = "Press K1 to exit";
					LCD_DrawString_Color ( ( usScreenWidth - ( strlen ( pStr ) - 7 ) * WIDTH_EN_CHAR ) >> 2, usScreenHeight >> 1, pStr, BACKGROUND, BLUE_C);

					LCD_Clear (0, 0, 240, 320, BLUE_B);
					pStr = "Press K1 to exit";
					LCD_DrawString_Color ( ( usScreenWidth - ( strlen ( pStr ) - 7 ) * WIDTH_EN_CHAR ) >> 2, usScreenHeight >> 1, pStr, BACKGROUND, BLUE_B);

					LCD_Clear (0, 0, 240, 320, BLUE_A);
					pStr = "Press K1 to exit";
					LCD_DrawString_Color ( ( usScreenWidth - ( strlen ( pStr ) - 7 ) * WIDTH_EN_CHAR ) >> 2, usScreenHeight >> 1, pStr, BACKGROUND, BLUE_A);

					LCD_Clear (0, 0, 240, 320, BLUE);
					pStr = "Press K1 to exit";
					LCD_DrawString_Color ( ( usScreenWidth - ( strlen ( pStr ) - 7 ) * WIDTH_EN_CHAR ) >> 2, usScreenHeight >> 1, pStr, BACKGROUND, BLUE);

					LCD_Clear (0, 0, 240, 320, BLUE_A);
					pStr = "Press K1 to exit";
					LCD_DrawString_Color ( ( usScreenWidth - ( strlen ( pStr ) - 7 ) * WIDTH_EN_CHAR ) >> 2, usScreenHeight >> 1, pStr, BACKGROUND, BLUE_A);

					LCD_Clear (0, 0, 240, 320, BLUE_B);
					pStr = "Press K1 to exit";
					LCD_DrawString_Color ( ( usScreenWidth - ( strlen ( pStr ) - 7 ) * WIDTH_EN_CHAR ) >> 2, usScreenHeight >> 1, pStr, BACKGROUND, BLUE_B);

					LCD_Clear (0, 0, 240, 320, BLUE_C);
					pStr = "Press K1 to exit";
					LCD_DrawString_Color ( ( usScreenWidth - ( strlen ( pStr ) - 7 ) * WIDTH_EN_CHAR ) >> 2, usScreenHeight >> 1, pStr, BACKGROUND, BLUE_C);

					break;
				case 6:
					LCD_Clear (0, 0, 240, 320, MAGENTA_C);
					pStr = "Press K1 to exit";
					LCD_DrawString_Color ( ( usScreenWidth - ( strlen ( pStr ) - 7 ) * WIDTH_EN_CHAR ) >> 2, usScreenHeight >> 1, pStr, BACKGROUND, MAGENTA_C);

					LCD_Clear (0, 0, 240, 320, MAGENTA_B);
					pStr = "Press K1 to exit";
					LCD_DrawString_Color ( ( usScreenWidth - ( strlen ( pStr ) - 7 ) * WIDTH_EN_CHAR ) >> 2, usScreenHeight >> 1, pStr, BACKGROUND, MAGENTA_B);

					LCD_Clear (0, 0, 240, 320, MAGENTA_A);
					pStr = "Press K1 to exit";
					LCD_DrawString_Color ( ( usScreenWidth - ( strlen ( pStr ) - 7 ) * WIDTH_EN_CHAR ) >> 2, usScreenHeight >> 1, pStr, BACKGROUND, MAGENTA_A);

					LCD_Clear (0, 0, 240, 320, MAGENTA);
					pStr = "Press K1 to exit";
					LCD_DrawString_Color ( ( usScreenWidth - ( strlen ( pStr ) - 7 ) * WIDTH_EN_CHAR ) >> 2, usScreenHeight >> 1, pStr, BACKGROUND, MAGENTA);

					LCD_Clear (0, 0, 240, 320, MAGENTA_A);
					pStr = "Press K1 to exit";
					LCD_DrawString_Color ( ( usScreenWidth - ( strlen ( pStr ) - 7 ) * WIDTH_EN_CHAR ) >> 2, usScreenHeight >> 1, pStr, BACKGROUND, MAGENTA_A);

					LCD_Clear (0, 0, 240, 320, MAGENTA_B);
					pStr = "Press K1 to exit";
					LCD_DrawString_Color ( ( usScreenWidth - ( strlen ( pStr ) - 7 ) * WIDTH_EN_CHAR ) >> 2, usScreenHeight >> 1, pStr, BACKGROUND, MAGENTA_B);

					LCD_Clear (0, 0, 240, 320, MAGENTA_C);
					pStr = "Press K1 to exit";
					LCD_DrawString_Color ( ( usScreenWidth - ( strlen ( pStr ) - 7 ) * WIDTH_EN_CHAR ) >> 2, usScreenHeight >> 1, pStr, BACKGROUND, MAGENTA_C);

					break;
				case 7:
					LCD_Clear (0, 0, 240, 320, RED);
					pStr = "Press K1 to exit";
					LCD_DrawString_Color ( ( usScreenWidth - ( strlen ( pStr ) - 7 ) * WIDTH_EN_CHAR ) >> 2, usScreenHeight >> 1, pStr, BACKGROUND, RED);

					LCD_Clear (0, 0, 240, 320, ORANGE);
					pStr = "Press K1 to exit";
					LCD_DrawString_Color ( ( usScreenWidth - ( strlen ( pStr ) - 7 ) * WIDTH_EN_CHAR ) >> 2, usScreenHeight >> 1, pStr, BACKGROUND, ORANGE);

					LCD_Clear (0, 0, 240, 320, YELLOW);
					pStr = "Press K1 to exit";
					LCD_DrawString_Color ( ( usScreenWidth - ( strlen ( pStr ) - 7 ) * WIDTH_EN_CHAR ) >> 2, usScreenHeight >> 1, pStr, BACKGROUND, YELLOW);

					LCD_Clear (0, 0, 240, 320, GREEN);
					pStr = "Press K1 to exit";
					LCD_DrawString_Color ( ( usScreenWidth - ( strlen ( pStr ) - 7 ) * WIDTH_EN_CHAR ) >> 2, usScreenHeight >> 1, pStr, BACKGROUND, GREEN);

					LCD_Clear (0, 0, 240, 320, CYAN);
					pStr = "Press K1 to exit";
					LCD_DrawString_Color ( ( usScreenWidth - ( strlen ( pStr ) - 7 ) * WIDTH_EN_CHAR ) >> 2, usScreenHeight >> 1, pStr, BACKGROUND, CYAN);

					LCD_Clear (0, 0, 240, 320, BLUE);
					pStr = "Press K1 to exit";
					LCD_DrawString_Color ( ( usScreenWidth - ( strlen ( pStr ) - 7 ) * WIDTH_EN_CHAR ) >> 2, usScreenHeight >> 1, pStr, BACKGROUND, BLUE);

					LCD_Clear (0, 0, 240, 320, MAGENTA);
					pStr = "Press K1 to exit";
					LCD_DrawString_Color ( ( usScreenWidth - ( strlen ( pStr ) - 7 ) * WIDTH_EN_CHAR ) >> 2, usScreenHeight >> 1, pStr, BACKGROUND, MAGENTA);

					break;
				case 8:
					LCD_Clear (0, 0, 240, 320, BACKGROUND);
					pStr = "Press K1 to exit";
					LCD_DrawString_Color ( ( usScreenWidth - ( strlen ( pStr ) - 7 ) * WIDTH_EN_CHAR ) >> 2, usScreenHeight >> 1, pStr, BACKGROUND, BLACK);

					LCD_Clear (0, 0, 240, 320, GREY);
					pStr = "Press K1 to exit";
					LCD_DrawString_Color ( ( usScreenWidth - ( strlen ( pStr ) - 7 ) * WIDTH_EN_CHAR ) >> 2, usScreenHeight >> 1, pStr, GREY, BLACK);

					LCD_Clear (0, 0, 240, 320, BLACK);
					pStr = "Press K1 to exit";
					LCD_DrawString_Color ( ( usScreenWidth - ( strlen ( pStr ) - 7 ) * WIDTH_EN_CHAR ) >> 2, usScreenHeight >> 1, pStr, BLACK, BACKGROUND);

					LCD_Clear (0, 0, 240, 320, GREY);
					pStr = "Press K1 to exit";
					LCD_DrawString_Color ( ( usScreenWidth - ( strlen ( pStr ) - 7 ) * WIDTH_EN_CHAR ) >> 2, usScreenHeight >> 1, pStr, GREY, BLACK);

					break;
			}
			if (kay == 1) {
				kay = 0;
				drawGUIFlag = 1;
				if (colourP == 7 || colourP == 8) colourP = 0;
        curGUITask = mainMenuTask;
			}
      break;
      case configMenuTask:

			/* Main menu */
			if (drawGUIFlag) {
				drawGUIFlag = 0;
				LCD_Clear(0, 0, 240, 320, BACKGROUND);

				LCD_DrawBox(8, 8, 48, 48, BLACK);
				pStr = "BACK";
				LCD_DrawString_Color ( 16, 24, pStr, BACKGROUND, BLACK );

				pStr = "Config";			// Title
				LCD_DrawString_Color ( 64, 24, pStr, BACKGROUND, BLACK );

				/* Options rendering */
				LCD_DrawBox(176, 64, 48, 48, BLACK);
				pStr = "Audio FX";
				LCD_DrawString_Color (104, 80, pStr, BACKGROUND, BLACK );
				/* Icon */
				LCD_DrawBox(184, 80, 8, 16, BLACK);
				LCD_DrawEllipse (194, 88, 12, 6, BLACK);
				LCD_DrawEllipse (202, 88, 16, 6, BLACK);
				LCD_DrawEllipse (210, 88, 20, 6, BLACK);

				LCD_DrawBox(176, 128, 48, 48, BLACK);
				pStr = "Display";
				LCD_DrawString_Color (112, 144, pStr, BACKGROUND, BLACK );
				/* Icon */
				// Vertical deco
				LCD_DrawLine (200, 132, 200, 136, BLACK );
				LCD_DrawLine (200, 168, 200, 172, BLACK );
				// Horizontal deco
				LCD_DrawLine (216, 152, 220, 152, BLACK );
				LCD_DrawLine (180, 152, 184, 152, BLACK );
				// Slanted deco
				LCD_DrawLine (182, 134, 186, 138, BLACK );
				LCD_DrawLine (182, 170, 186, 166, BLACK );
				LCD_DrawLine (218, 134, 214, 138, BLACK );
				LCD_DrawLine (218, 170, 214, 166, BLACK );
				LCD_DrawEllipse (200, 152, 12, 12, BLACK);

				LCD_DrawBox(176, 192, 48, 48, BLACK);
				pStr = "Dynamic Vibration";
				LCD_DrawString_Color (32, 208, pStr, BACKGROUND, BLACK );
				/* Icon */
				LCD_DrawBox(182, 198, 36, 36, BLACK);
				LCD_DrawEllipse (200, 216, 12, 12, BLACK);

				LCD_DrawBox(176, 256, 48, 48, BLACK);
				pStr = "Options";
				/* Icon */
				LCD_DrawString_Color (112, 272, pStr, BACKGROUND, BLACK );
				LCD_DrawEllipse (200, 280, 12, 12, BLACK);
			}

			// Main dish :)
			if ( ucXPT2046_TouchFlag == 1 ) {
				actionFlag = configButton();
				ucXPT2046_TouchFlag = 0;
				drawButtonsFlag = 1;
				switch (actionFlag) {
					case 0: drawGUIFlag = 1; curGUITask = mainMenuTask; break;
					case 1: drawGUIFlag = 1; curGUITask = audiofxConfigTask; break;
					case 2: drawGUIFlag = 1; curGUITask = displayConfigTask; break;
					case 3: drawGUIFlag = 1; curGUITask = dvConfigTask; break;
					case 4: drawGUIFlag = 1; curGUITask = hiddenConfigTask; break;
				}
			}
      break;
      case mainMenuTask:

      //	if (updateLCDStartPlay) {
      //		LCD_DrawString(100, 100, "Press to start playing");
      //		updateLCDStartPlay = 0;
      //	}
			/* Main menu */
			if (drawGUIFlag) {
        drawGUIFlag = 0;
				LCD_Clear(0, 0, 240, 320, BACKGROUND);

				pStr = "Stream Deck";			// Title
				LCD_DrawString_Color ( 8, 8, pStr, BACKGROUND, BLACK );

				/* Options rendering */
				LCD_DrawBox(176, 32, 48, 48, BLACK);
				pStr = "K1: Return";
				LCD_DrawString_Color (32, 40, pStr, BACKGROUND, BLACK );
				pStr = "K2: Play/Pause";
				LCD_DrawString_Color (32, 56, pStr, BACKGROUND, BLACK );
				/* Icon */
				LCD_DrawBox(184, 48, 8, 16, BLACK);
				LCD_DrawEllipse (194, 56, 12, 6, BLACK);
				LCD_DrawEllipse (202, 56, 16, 6, BLACK);
				LCD_DrawEllipse (210, 56, 20, 6, BLACK);

				LCD_DrawBox(176, 96, 48, 48, BLACK);
				// pStr = "Loaded filename:";
        pStr = "SD card status:";
				LCD_DrawString_Color (32, 104, pStr, BACKGROUND, BLACK );
				// Loaded filename
				// pStr = (myPath[0] == 0) ? "No file loaded" : myPath;
        pStr = (SDCardStatus == 0) ? "No SD card" : "SD card inserted";
				LCD_DrawString_Color (32, 120, pStr, BACKGROUND, BLACK );
				/* Icon */
				LCD_DrawEllipse (200, 120, 12, 12, BLACK);

				// LCD_DrawBox(176, 160, 48, 48, BLACK);
				// pStr = "Play/Pause";
				// LCD_DrawString_Color (32, 176, pStr, BACKGROUND, BLACK );
				/* Icon */
				// LCD_DrawLine(192, 172, 192, 196, BLACK);
				// LCD_DrawLine(192, 172, 212, 184, BLACK);
				// LCD_DrawLine(192, 196, 212, 184, BLACK);

				LCD_DrawBox(176, 160, 48, 48, BLACK);
				pStr = "Config";
				LCD_DrawString_Color (32, 176, pStr, BACKGROUND, BLACK );
				/* Icon 1 */
				LCD_DrawLine(192, 172, 192, 196, BLACK);
				LCD_DrawLine(192, 172, 212, 184, BLACK);
				LCD_DrawLine(192, 196, 212, 184, BLACK);
				/* Icon 2 */
				// // Vertical deco
				// LCD_DrawLine (200, 164, 200, 168, BLACK );
				// LCD_DrawLine (200, 200, 200, 204, BLACK );
				// // Horizontal deco
				// LCD_DrawLine (216, 184, 220, 184, BLACK );
				// LCD_DrawLine (180, 184, 184, 184, BLACK );
				// // Slanted deco
				// LCD_DrawLine (182, 166, 186, 170, BLACK );
				// LCD_DrawLine (182, 202, 186, 198, BLACK );
				// LCD_DrawLine (218, 166, 214, 170, BLACK );
				// LCD_DrawLine (218, 202, 214, 198, BLACK );
				// LCD_DrawEllipse (200, 184, 12, 12, BLACK);
			}

			// Main dish :)
			if ( ucXPT2046_TouchFlag == 1 ) {
				actionFlag = menuButton();
				ucXPT2046_TouchFlag = 0;
				switch (actionFlag) {
					case 0: break;		// Dummy button
					case 1: break;		// Dummy button 2
					case 2: drawGUIFlag = 1; curGUITask = configMenuTask; break;
				}
			}
      break;
      }
      HAL_Delay(100);
    }
      /* USER CODE END WHILE */
  }

  /* USER CODE END 3 */
}

void SystemClock_Config(void)
{
  RCC_OscInitTypeDef RCC_OscInitStruct = {0};
  RCC_ClkInitTypeDef RCC_ClkInitStruct = {0};
  RCC_PeriphCLKInitTypeDef PeriphClkInit = {0};

  /** Initializes the RCC Oscillators according to the specified parameters
  * in the RCC_OscInitTypeDef structure.
  */
  RCC_OscInitStruct.OscillatorType = RCC_OSCILLATORTYPE_HSE;
  RCC_OscInitStruct.HSEState = RCC_HSE_ON;
  RCC_OscInitStruct.HSEPredivValue = RCC_HSE_PREDIV_DIV1;
  RCC_OscInitStruct.HSIState = RCC_HSI_ON;
  RCC_OscInitStruct.PLL.PLLState = RCC_PLL_ON;
  RCC_OscInitStruct.PLL.PLLSource = RCC_PLLSOURCE_HSE;
  RCC_OscInitStruct.PLL.PLLMUL = RCC_PLL_MUL9;
  if (HAL_RCC_OscConfig(&RCC_OscInitStruct) != HAL_OK)
  {
    Error_Handler();
  }

  /** Initializes the CPU, AHB and APB buses clocks
  */
  RCC_ClkInitStruct.ClockType = RCC_CLOCKTYPE_HCLK|RCC_CLOCKTYPE_SYSCLK
                              |RCC_CLOCKTYPE_PCLK1|RCC_CLOCKTYPE_PCLK2;
  RCC_ClkInitStruct.SYSCLKSource = RCC_SYSCLKSOURCE_PLLCLK;
  RCC_ClkInitStruct.AHBCLKDivider = RCC_SYSCLK_DIV1;
  RCC_ClkInitStruct.APB1CLKDivider = RCC_HCLK_DIV2;
  RCC_ClkInitStruct.APB2CLKDivider = RCC_HCLK_DIV1;

  if (HAL_RCC_ClockConfig(&RCC_ClkInitStruct, FLASH_LATENCY_2) != HAL_OK)
  {
    Error_Handler();
  }
  PeriphClkInit.PeriphClockSelection = RCC_PERIPHCLK_ADC|RCC_PERIPHCLK_I2S2;
  PeriphClkInit.AdcClockSelection = RCC_ADCPCLK2_DIV6;
  PeriphClkInit.I2s2ClockSelection = RCC_I2S2CLKSOURCE_SYSCLK;
  if (HAL_RCCEx_PeriphCLKConfig(&PeriphClkInit) != HAL_OK)
  {
    Error_Handler();
  }
  HAL_RCC_MCOConfig(RCC_MCO, RCC_MCO1SOURCE_PLLCLK, RCC_MCODIV_1);
}

static void MX_ADC2_Init(void)
{

  ADC_ChannelConfTypeDef sConfig = {0};

  /** Common config
  */
  hadc2.Instance = ADC2;
  hadc2.Init.ScanConvMode = ADC_SCAN_DISABLE;
  hadc2.Init.ContinuousConvMode = DISABLE;
  hadc2.Init.DiscontinuousConvMode = DISABLE;
  hadc2.Init.ExternalTrigConv = ADC_SOFTWARE_START;
  hadc2.Init.DataAlign = ADC_DATAALIGN_RIGHT;
  hadc2.Init.NbrOfConversion = 1;
  if (HAL_ADC_Init(&hadc2) != HAL_OK)
  {
    Error_Handler();
  }

  /** Configure Regular Channel
  */
  sConfig.Channel = ADC_CHANNEL_4;
  sConfig.Rank = ADC_REGULAR_RANK_1;
  sConfig.SamplingTime = ADC_SAMPLETIME_55CYCLES_5;
  if (HAL_ADC_ConfigChannel(&hadc2, &sConfig) != HAL_OK)
  {
    Error_Handler();
  }

}

static void MX_I2S2_Init(void)
{

  hi2s2.Instance = SPI2;
  hi2s2.Init.Mode = I2S_MODE_MASTER_TX;
  hi2s2.Init.Standard = I2S_STANDARD_PHILIPS;
  hi2s2.Init.DataFormat = I2S_DATAFORMAT_16B_EXTENDED;
  hi2s2.Init.MCLKOutput = I2S_MCLKOUTPUT_ENABLE;
  hi2s2.Init.AudioFreq = I2S_AUDIOFREQ_16K;
  hi2s2.Init.CPOL = I2S_CPOL_LOW;
  if (HAL_I2S_Init(&hi2s2) != HAL_OK)
  {
    Error_Handler();
  }

}

static void MX_SDIO_SD_Init(void)
{

  hsd.Instance = SDIO;
  hsd.Init.ClockEdge = SDIO_CLOCK_EDGE_RISING;
  hsd.Init.ClockBypass = SDIO_CLOCK_BYPASS_DISABLE;
  hsd.Init.ClockPowerSave = SDIO_CLOCK_POWER_SAVE_DISABLE;
  hsd.Init.BusWide = SDIO_BUS_WIDE_1B;
  hsd.Init.HardwareFlowControl = SDIO_HARDWARE_FLOW_CONTROL_DISABLE;
  hsd.Init.ClockDiv = 4;

}

static void MX_TIM1_Init(void)
{

  TIM_ClockConfigTypeDef sClockSourceConfig = {0};
  TIM_MasterConfigTypeDef sMasterConfig = {0};

  htim1.Instance = TIM1;
  htim1.Init.Prescaler = 72-1;
  htim1.Init.CounterMode = TIM_COUNTERMODE_UP;
  htim1.Init.Period = 100-1;
  htim1.Init.ClockDivision = TIM_CLOCKDIVISION_DIV1;
  htim1.Init.RepetitionCounter = 0;
  htim1.Init.AutoReloadPreload = TIM_AUTORELOAD_PRELOAD_DISABLE;
  if (HAL_TIM_Base_Init(&htim1) != HAL_OK)
  {
    Error_Handler();
  }
  sClockSourceConfig.ClockSource = TIM_CLOCKSOURCE_INTERNAL;
  if (HAL_TIM_ConfigClockSource(&htim1, &sClockSourceConfig) != HAL_OK)
  {
    Error_Handler();
  }
  sMasterConfig.MasterOutputTrigger = TIM_TRGO_UPDATE;
  sMasterConfig.MasterSlaveMode = TIM_MASTERSLAVEMODE_DISABLE;
  if (HAL_TIMEx_MasterConfigSynchronization(&htim1, &sMasterConfig) != HAL_OK)
  {
    Error_Handler();
  }

}

static void MX_TIM2_Init(void)
{

  TIM_ClockConfigTypeDef sClockSourceConfig = {0};
  TIM_MasterConfigTypeDef sMasterConfig = {0};
  TIM_OC_InitTypeDef sConfigOC = {0};

  htim2.Instance = TIM2;
  htim2.Init.Prescaler = 72-1;
  htim2.Init.CounterMode = TIM_COUNTERMODE_UP;
  htim2.Init.Period = 1000-1;
  htim2.Init.ClockDivision = TIM_CLOCKDIVISION_DIV1;
  htim2.Init.AutoReloadPreload = TIM_AUTORELOAD_PRELOAD_DISABLE;
  if (HAL_TIM_Base_Init(&htim2) != HAL_OK)
  {
    Error_Handler();
  }
  sClockSourceConfig.ClockSource = TIM_CLOCKSOURCE_INTERNAL;
  if (HAL_TIM_ConfigClockSource(&htim2, &sClockSourceConfig) != HAL_OK)
  {
    Error_Handler();
  }
  if (HAL_TIM_PWM_Init(&htim2) != HAL_OK)
  {
    Error_Handler();
  }
  sMasterConfig.MasterOutputTrigger = TIM_TRGO_UPDATE;
  sMasterConfig.MasterSlaveMode = TIM_MASTERSLAVEMODE_DISABLE;
  if (HAL_TIMEx_MasterConfigSynchronization(&htim2, &sMasterConfig) != HAL_OK)
  {
    Error_Handler();
  }
  sConfigOC.OCMode = TIM_OCMODE_PWM1;
  sConfigOC.Pulse = 500;
  sConfigOC.OCPolarity = TIM_OCPOLARITY_HIGH;
  sConfigOC.OCFastMode = TIM_OCFAST_DISABLE;
  if (HAL_TIM_PWM_ConfigChannel(&htim2, &sConfigOC, TIM_CHANNEL_3) != HAL_OK)
  {
    Error_Handler();
  }
  HAL_TIM_MspPostInit(&htim2);

}

static void MX_DMA_Init(void)
{

  /* DMA controller clock enable */
  __HAL_RCC_DMA1_CLK_ENABLE();

  /* DMA interrupt init */
  /* DMA1_Channel5_IRQn interrupt configuration */
  HAL_NVIC_SetPriority(DMA1_Channel5_IRQn, 0, 0);
  HAL_NVIC_EnableIRQ(DMA1_Channel5_IRQn);

}

static void MX_GPIO_Init(void)
{
  GPIO_InitTypeDef GPIO_InitStruct = {0};

  /* GPIO Ports Clock Enable */
  __HAL_RCC_GPIOE_CLK_ENABLE();
  __HAL_RCC_GPIOC_CLK_ENABLE();
  __HAL_RCC_GPIOA_CLK_ENABLE();
  __HAL_RCC_GPIOB_CLK_ENABLE();
  __HAL_RCC_GPIOD_CLK_ENABLE();

  /*Configure GPIO pin Output Level */
  HAL_GPIO_WritePin(GPIOE, GPIO_PIN_2|GPIO_PIN_0|GPIO_PIN_1, GPIO_PIN_RESET);

  /*Configure GPIO pin Output Level */
  HAL_GPIO_WritePin(GPIOA, GPIO_PIN_5, GPIO_PIN_RESET);

  /*Configure GPIO pin Output Level */
  HAL_GPIO_WritePin(GPIOB, GPIO_PIN_0|GPIO_PIN_1|GPIO_PIN_5, GPIO_PIN_SET);

  /*Configure GPIO pin Output Level */
  HAL_GPIO_WritePin(GPIOD, GPIO_PIN_12|GPIO_PIN_13, GPIO_PIN_RESET);

  /*Configure GPIO pins : PE2 PE0 PE1 */
  GPIO_InitStruct.Pin = GPIO_PIN_2|GPIO_PIN_0|GPIO_PIN_1;
  GPIO_InitStruct.Mode = GPIO_MODE_OUTPUT_PP;
  GPIO_InitStruct.Pull = GPIO_NOPULL;
  GPIO_InitStruct.Speed = GPIO_SPEED_FREQ_HIGH;
  HAL_GPIO_Init(GPIOE, &GPIO_InitStruct);

  /*Configure GPIO pin : PE3 */
  GPIO_InitStruct.Pin = GPIO_PIN_3;
  GPIO_InitStruct.Mode = GPIO_MODE_INPUT;
  GPIO_InitStruct.Pull = GPIO_PULLUP;
  HAL_GPIO_Init(GPIOE, &GPIO_InitStruct);

  /*Configure GPIO pin : PE4 */
  GPIO_InitStruct.Pin = GPIO_PIN_4;
  GPIO_InitStruct.Mode = GPIO_MODE_IT_FALLING;
  GPIO_InitStruct.Pull = GPIO_PULLUP;
  HAL_GPIO_Init(GPIOE, &GPIO_InitStruct);

  /*Configure GPIO pin : PC13 */
  GPIO_InitStruct.Pin = GPIO_PIN_13;
  GPIO_InitStruct.Mode = GPIO_MODE_IT_RISING;
  GPIO_InitStruct.Pull = GPIO_PULLDOWN;
  HAL_GPIO_Init(GPIOC, &GPIO_InitStruct);

  /*Configure GPIO pin : PC0 */
  GPIO_InitStruct.Pin = GPIO_PIN_0;
  GPIO_InitStruct.Mode = GPIO_MODE_INPUT;
  GPIO_InitStruct.Pull = GPIO_PULLDOWN;
  HAL_GPIO_Init(GPIOC, &GPIO_InitStruct);

  /*Configure GPIO pin : PA0 */
  GPIO_InitStruct.Pin = GPIO_PIN_0;
  GPIO_InitStruct.Mode = GPIO_MODE_IT_RISING;
  GPIO_InitStruct.Pull = GPIO_PULLDOWN;
  HAL_GPIO_Init(GPIOA, &GPIO_InitStruct);

  /*Configure GPIO pin : PA5 */
  GPIO_InitStruct.Pin = GPIO_PIN_5;
  GPIO_InitStruct.Mode = GPIO_MODE_OUTPUT_PP;
  GPIO_InitStruct.Pull = GPIO_NOPULL;
  GPIO_InitStruct.Speed = GPIO_SPEED_FREQ_HIGH;
  HAL_GPIO_Init(GPIOA, &GPIO_InitStruct);

  /*Configure GPIO pins : PB0 PB1 PB5 */
  GPIO_InitStruct.Pin = GPIO_PIN_0|GPIO_PIN_1|GPIO_PIN_5;
  GPIO_InitStruct.Mode = GPIO_MODE_OUTPUT_PP;
  GPIO_InitStruct.Pull = GPIO_NOPULL;
  GPIO_InitStruct.Speed = GPIO_SPEED_FREQ_HIGH;
  HAL_GPIO_Init(GPIOB, &GPIO_InitStruct);

  /*Configure GPIO pins : PD12 PD13 */
  GPIO_InitStruct.Pin = GPIO_PIN_12|GPIO_PIN_13;
  GPIO_InitStruct.Mode = GPIO_MODE_OUTPUT_PP;
  GPIO_InitStruct.Pull = GPIO_NOPULL;
  GPIO_InitStruct.Speed = GPIO_SPEED_FREQ_HIGH;
  HAL_GPIO_Init(GPIOD, &GPIO_InitStruct);

  /*Configure GPIO pin : PA8 */
  GPIO_InitStruct.Pin = GPIO_PIN_8;
  GPIO_InitStruct.Mode = GPIO_MODE_AF_PP;
  GPIO_InitStruct.Speed = GPIO_SPEED_FREQ_LOW;
  HAL_GPIO_Init(GPIOA, &GPIO_InitStruct);

  /* EXTI interrupt init*/
  HAL_NVIC_SetPriority(EXTI0_IRQn, 0, 0);
  HAL_NVIC_EnableIRQ(EXTI0_IRQn);

  HAL_NVIC_SetPriority(EXTI4_IRQn, 0, 0);
  HAL_NVIC_EnableIRQ(EXTI4_IRQn);

  HAL_NVIC_SetPriority(EXTI15_10_IRQn, 0, 0);
  HAL_NVIC_EnableIRQ(EXTI15_10_IRQn);

}

/* FSMC initialization function */
static void MX_FSMC_Init(void)
{

  FSMC_NORSRAM_TimingTypeDef Timing = {0};

  /** Perform the SRAM1 memory initialization sequence
  */
  hsram1.Instance = FSMC_NORSRAM_DEVICE;
  hsram1.Extended = FSMC_NORSRAM_EXTENDED_DEVICE;
  /* hsram1.Init */
  hsram1.Init.NSBank = FSMC_NORSRAM_BANK1;
  hsram1.Init.DataAddressMux = FSMC_DATA_ADDRESS_MUX_DISABLE;
  hsram1.Init.MemoryType = FSMC_MEMORY_TYPE_SRAM;
  hsram1.Init.MemoryDataWidth = FSMC_NORSRAM_MEM_BUS_WIDTH_16;
  hsram1.Init.BurstAccessMode = FSMC_BURST_ACCESS_MODE_DISABLE;
  hsram1.Init.WaitSignalPolarity = FSMC_WAIT_SIGNAL_POLARITY_LOW;
  hsram1.Init.WrapMode = FSMC_WRAP_MODE_DISABLE;
  hsram1.Init.WaitSignalActive = FSMC_WAIT_TIMING_BEFORE_WS;
  hsram1.Init.WriteOperation = FSMC_WRITE_OPERATION_ENABLE;
  hsram1.Init.WaitSignal = FSMC_WAIT_SIGNAL_DISABLE;
  hsram1.Init.ExtendedMode = FSMC_EXTENDED_MODE_DISABLE;
  hsram1.Init.AsynchronousWait = FSMC_ASYNCHRONOUS_WAIT_DISABLE;
  hsram1.Init.WriteBurst = FSMC_WRITE_BURST_DISABLE;
  /* Timing */
  Timing.AddressSetupTime = 15;
  Timing.AddressHoldTime = 15;
  Timing.DataSetupTime = 255;
  Timing.BusTurnAroundDuration = 15;
  Timing.CLKDivision = 16;
  Timing.DataLatency = 17;
  Timing.AccessMode = FSMC_ACCESS_MODE_A;
  /* ExtTiming */

  if (HAL_SRAM_Init(&hsram1, &Timing, NULL) != HAL_OK)
  {
    Error_Handler( );
  }

  /** Disconnect NADV
  */

  __HAL_AFIO_FSMCNADV_DISCONNECTED();

}

void Error_Handler(void)
{
  __disable_irq();
  while (1)
  {
  }
}
